AUTOSAR XML (schema 4-2-1)
package /ComponentTypes
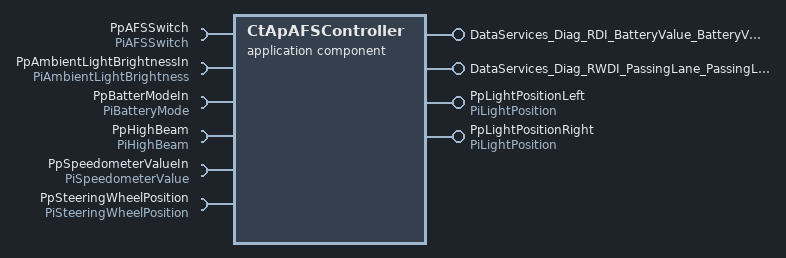
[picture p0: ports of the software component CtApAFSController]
  application sw component type CtApAFSController
    4 x provide port:
      DataServices_Diag_RDI_BatteryValue_BatteryValue: provided-com-specs=[{operation=ConditionCheckRead, queue-length=1}, {operation=ReadData, queue-length=1}], provided-interface=DataServices_Diag_RDI_BatteryValue_BatteryValue
      DataServices_Diag_RWDI_PassingLane_PassingLane_PassingLane: provided-interface=DataServices_Diag_RWDI_PassingLane_PassingLane_PassingLane
        provided-com-specs:
          operation=ConditionCheckRead, queue-length=1
          operation=ReadData, queue-length=1
          operation=WriteData, queue-length=1
      PpLightPositionLeft: provided-com-specs=[{data-element=DeLightLength, init-value=0}, {data-element=DeLightPosition, init-value=0}], provided-interface=PiLightPosition
      PpLightPositionRight: provided-interface=PiLightPosition
        provided-com-specs:
          data-element=DeLightLength, init-value=0
          data-element=DeLightPosition, init-value=constant-reference=CDarkLight
    6 x require port:
      PpAFSSwitch: required-interface=PiAFSSwitch
      PpAmbientLightBrightnessIn: nonqueued-receiver-com-spec{data-element=DeAmbientLightBrightness, filter=data-filter-type=ALWAYS, init-value=0}, required-interface=PiAmbientLightBrightness
      PpBatterModeIn: mode-switch-receiver-com-spec{enhanced-mode-api=false, supports-asynchronous-mode-switch=false}, required-interface=PiBatteryMode
      PpHighBeam: required-interface=PiHighBeam
      PpSpeedometerValueIn: nonqueued-receiver-com-spec{data-element=DeSpeedometerValue, filter=data-filter-type=ALWAYS, init-value=0}, required-interface=PiSpeedometerValue
      PpSteeringWheelPosition: nonqueued-receiver-com-spec{data-element=DeSteeringWheelPosition, filter=data-filter-type=ALWAYS, init-value=0}, required-interface=PiSteeringWheelPosition
    behavior CtApAFSController_InternalBehavior: data-type-mapping=ApMappingSet
      5 x operation invoked event:
        OIT_DataServices_Diag_RDI_BatteryValue_BatteryValue_ConditionCheckRead_DataServices_Diag_RDI_BatteryValue_BatteryValue_C3B28864A: start-on-event=DataServices_Diag_RDI_BatteryValue_BatteryValue_ConditionCheckRead, operation=DataServices_Diag_RDI_BatteryValue_BatteryValue.ConditionCheckRead
        OIT_DataServices_Diag_RDI_BatteryValue_BatteryValue_ReadData_DataServices_Diag_RDI_BatteryValue_BatteryValue_ReadData: start-on-event=DataServices_Diag_RDI_BatteryValue_BatteryValue_ReadData, operation=DataServices_Diag_RDI_BatteryValue_BatteryValue.ReadData
        OIT_DataServices_Diag_RWDI_PassingLane_PassingLane_PassingLane_ConditionCheckRead_DataServices_Diag_RWDI_PassingLane_Pas5F15AC2B: start-on-event=DataServices_Diag_RWDI_PassingLane_PassingLane_PassingLane_ConditionCheckRead, operation=DataServices_Diag_RWDI_PassingLane_PassingLane_PassingLane.ConditionCheckRead
        OIT_DataServices_Diag_RWDI_PassingLane_PassingLane_PassingLane_ReadData_DataServices_Diag_RWDI_PassingLane_PassingLane_P8D71540F: start-on-event=DataServices_Diag_RWDI_PassingLane_PassingLane_PassingLane_ReadData, operation=DataServices_Diag_RWDI_PassingLane_PassingLane_PassingLane.ReadData
        OIT_DataServices_Diag_RWDI_PassingLane_PassingLane_PassingLane_WriteData_DataServices_Diag_RWDI_PassingLane_PassingLane_DA0BE9C4: start-on-event=DataServices_Diag_RWDI_PassingLane_PassingLane_PassingLane_WriteData, operation=DataServices_Diag_RWDI_PassingLane_PassingLane_PassingLane.WriteData
      init event CtApAFSController_InitEvent: start-on-event=RCtApAFSController_Init
      data received event DRT_RCtApAFSControllerLogic_PpAmbientLightBrightnessIn_DeAmbientLightBrightness: disabled-mode=PpBatterModeIn.BatteryModes.BATTERY_LOW, start-on-event=RCtApAFSControllerLogic, data=PpAmbientLightBrightnessIn.DeAmbientLightBrightness
      data received event DRT_RCtApAFSControllerLogic_PpSpeedometerValueIn_DeSpeedometerValue: disabled-mode=PpBatterModeIn.BatteryModes.BATTERY_LOW, start-on-event=RCtApAFSControllerLogic, data=PpSpeedometerValueIn.DeSpeedometerValue
      data received event DRT_RCtApAFSControllerLogic_PpSteeringWheelPosition_DeSteeringWheelPosition: disabled-mode=PpBatterModeIn.BatteryModes.BATTERY_LOW, start-on-event=RCtApAFSControllerLogic, data=PpSteeringWheelPosition.DeSteeringWheelPosition
      swc mode switch event MST_RCtApLowBatteryLogic_1: disabled-mode=[PpBatterModeIn.BatteryModes.BATTERY_HIGH, PpBatterModeIn.BatteryModes.BATTERY_MEDIUM], start-on-event=RCtApLowBatteryLogic, activation=ON-ENTRY, mode=PpBatterModeIn.BatteryModes.BATTERY_LOW
      8 x runnable:
        DataServices_Diag_RDI_BatteryValue_BatteryValue_ConditionCheckRead
        DataServices_Diag_RDI_BatteryValue_BatteryValue_ReadData
        DataServices_Diag_RWDI_PassingLane_PassingLane_PassingLane_ConditionCheckRead
        DataServices_Diag_RWDI_PassingLane_PassingLane_PassingLane_ReadData
        DataServices_Diag_RWDI_PassingLane_PassingLane_PassingLane_WriteData
        RCtApAFSController_Init
        RCtApAFSControllerLogic
          data-receive-point-by-arguments:
            access REC_PpAmbientLightBrightnessIn_DeAmbientLightBrightness: accessed-variable=PpAmbientLightBrightnessIn.DeAmbientLightBrightness
            access REC_PpSpeedometerValueIn_DeSpeedometerValue: accessed-variable=PpSpeedometerValueIn.DeSpeedometerValue
            access REC_PpSteeringWheelPosition_DeSteeringWheelPosition: accessed-variable=PpSteeringWheelPosition.DeSteeringWheelPosition
          data-send-points:
            4 x access:
              SEND_PpLightPosition_DeLightPosition: accessed-variable=PpLightPositionLeft.DeLightPosition
              SEND_PpLightPositionLeft_DeLightMode: accessed-variable=PpLightPositionLeft.DeLightLength
              SEND_PpLightPositionRight_DeLightMode: accessed-variable=PpLightPositionRight.DeLightLength
              SEND_PpLightPositionRight_DeLightPosition: accessed-variable=PpLightPositionRight.DeLightPosition
          sync call SC_PpAFSSwitch_ReadChannel: operation=PpAFSSwitch.ReadChannel, timeout=0
          sync call SC_PpHighBeam_ReadChannel: operation=PpHighBeam.ReadChannel, timeout=0
        RCtApLowBatteryLogic
          data-send-points:
            4 x access:
              SEND_PpLightPositionLeft_DeLightLength: accessed-variable=PpLightPositionLeft.DeLightLength
              SEND_PpLightPositionLeft_DeLightPosition: accessed-variable=PpLightPositionLeft.DeLightPosition
              SEND_PpLightPositionRight_DeLightLength: accessed-variable=PpLightPositionRight.DeLightLength
              SEND_PpLightPositionRight_DeLightPosition: accessed-variable=PpLightPositionRight.DeLightPosition
          sync call SC_PpHighBeam_ReadChannel: operation=PpHighBeam.ReadChannel, timeout=0
  swc implementation CtApAFSController_Implementation: behavior=CtApAFSController_InternalBehavior
    code-descriptors:
      code Default: artifact-descriptors=autosar-engineering-object={short-label=Default, category=SWSRC}
